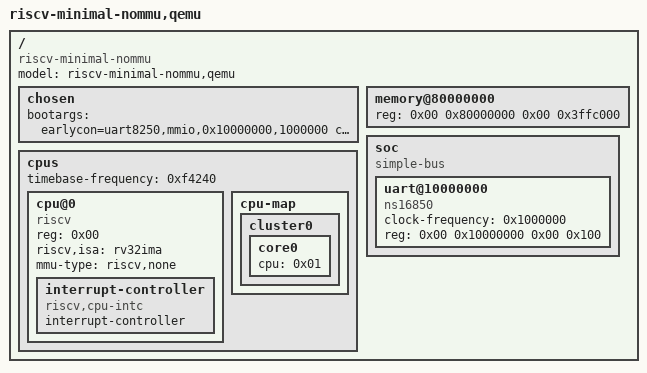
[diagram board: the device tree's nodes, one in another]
/dts-v1/;

/ {
	#address-cells = <0x02>;
	#size-cells = <0x02>;
	compatible = "riscv-minimal-nommu";
	model = "riscv-minimal-nommu,qemu";

	chosen {
		bootargs = "earlycon=uart8250,mmio,0x10000000,1000000 console=ttyS0";
	};

	memory@80000000 {
		device_type = "memory";
		reg = <0x00 0x80000000 0x00 0x3ffc000>;
	};

	cpus {
		#address-cells = <0x01>;
		#size-cells = <0x00>;
		timebase-frequency = <0xf4240>;

		cpu@0 {
			phandle = <0x01>;
			device_type = "cpu";
			reg = <0x00>;
			status = "okay";
			compatible = "riscv";
			riscv,isa = "rv32ima";
			mmu-type = "riscv,none";

			interrupt-controller {
				#interrupt-cells = <0x01>;
				interrupt-controller;
				compatible = "riscv,cpu-intc";
				phandle = <0x02>;
			};
		};

		cpu-map {
			cluster0 {
				core0 {
					cpu = <0x01>;
				};
			};
		};
	};

	soc {
		#address-cells = <0x02>;
		#size-cells = <0x02>;
		compatible = "simple-bus";
		ranges;

		uart@10000000 {
			clock-frequency = <0x1000000>;
			reg = <0x00 0x10000000 0x00 0x100>;
			compatible = "ns16850";
		};
	};
};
